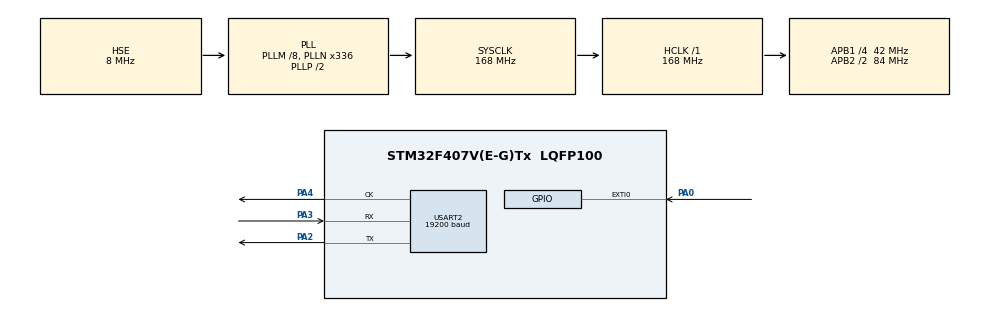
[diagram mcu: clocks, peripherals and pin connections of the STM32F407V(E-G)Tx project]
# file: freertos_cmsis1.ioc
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FREERTOS.Queues01=linCanQueue,16,uint16_t,0,Dynamic,NULL,NULL
FREERTOS.Tasks01=linReceiverTask,0,128,StartLinReceiverTask,Default,NULL,Dynamic,NULL,NULL;canSenderTask,-3,128,StartCanSenderTask,Default,NULL,Dynamic,NULL,NULL;myTask03,-3,128,StartTask03,Default,NULL,Dynamic,NULL,NULL
Mcu.Family=STM32F4
Mcu.Name=STM32F407V(E-G)Tx
Mcu.Package=LQFP100
NVIC.EXTI0_IRQn=true\:5\:0\:false\:false\:true\:true\:true\:true
NVIC.PriorityGroup=NVIC_PRIORITYGROUP_4
NVIC.TIM6_DAC_IRQn=true\:0\:0\:false\:false\:true\:false\:false\:true
NVIC.TimeBase=TIM6_DAC_IRQn
NVIC.TimeBaseIP=TIM6
PA0-WKUP.Signal=GPXTI0
PA13.Mode=Serial_Wire
PA13.Signal=SYS_JTMS-SWDIO
PA14.Mode=Serial_Wire
PA14.Signal=SYS_JTCK-SWCLK
PA2.Mode=Synchronous
PA2.Signal=USART2_TX
PA3.Mode=Synchronous
PA3.Signal=USART2_RX
PA4.Mode=Synchronous
PA4.Signal=USART2_CK
PH0-OSC_IN.Mode=HSE-External-Oscillator
PH0-OSC_IN.Signal=RCC_OSC_IN
PH1-OSC_OUT.Mode=HSE-External-Oscillator
PH1-OSC_OUT.Signal=RCC_OSC_OUT
ProjectManager.HeapSize=0x200
ProjectManager.StackSize=0x400
ProjectManager.TargetToolchain=STM32CubeIDE
RCC.48MHZClocksFreq_Value=48000000
RCC.AHBFreq_Value=168000000
RCC.APB1CLKDivider=RCC_HCLK_DIV4
RCC.APB1Freq_Value=42000000
RCC.APB1TimFreq_Value=84000000
RCC.APB2CLKDivider=RCC_HCLK_DIV2
RCC.APB2Freq_Value=84000000
RCC.APB2TimFreq_Value=168000000
RCC.CortexFreq_Value=168000000
RCC.HCLKFreq_Value=168000000
RCC.HSE_VALUE=8000000
RCC.HSI_VALUE=16000000
RCC.LSE_VALUE=32768
RCC.PLLM=8
RCC.PLLN=336
RCC.PLLQ=7
RCC.PLLSourceVirtual=RCC_PLLSOURCE_HSE
RCC.SYSCLKFreq_VALUE=168000000
RCC.SYSCLKSource=RCC_SYSCLKSOURCE_PLLCLK
RCC.VCOOutputFreq_Value=336000000
USART2.BaudRate=19200
USART2.VirtualMode=VM_SYNC
VP_FREERTOS_VS_CMSIS_V1.Mode=CMSIS_V1
VP_SYS_VS_tim6.Mode=TIM6
board=STM32F407G-DISC1

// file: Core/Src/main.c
/* USER CODE BEGIN Header */
/**
  ******************************************************************************
  * @file           : main.c
  * @brief          : Main program body
  ******************************************************************************
  * @attention
  *
  * Copyright (c) 2024 STMicroelectronics.
  * All rights reserved.
  *
  * This software is licensed under terms that can be found in the LICENSE file
  * in the root directory of this software component.
  * If no LICENSE file comes with this software, it is provided AS-IS.
  *
  ******************************************************************************
  */
/* USER CODE END Header */
#include "main.h"
#include "cmsis_os.h"

/* USER CODE BEGIN Includes */
#include <stdio.h>
#include "can.h"
#include "phares.h"
#include "commodos.h"
#include "UART_LIN.h"
#include "usart2.h"
#include "spi.h"
#include "lis3dsh.h"
/* USER CODE END Includes */

USART_HandleTypeDef husart2;

osThreadId linSenderTaskHandle;
osThreadId canReceiverTaskHandle;
osThreadId myTask04Handle;
osThreadId canTrackerTaskHandle;
osThreadId acceleroTaskHandle;
osMessageQId linCanQueueHandle;
osMutexId myMutex01Handle;
/* USER CODE BEGIN PV */

unsigned char DisplayData[];
LINMSG Tx_Msg;
LINMSG Rx_Msg;
int new_request;
int i = 0;
int actual_data;
int should_read_id = 0;
int should_read_data = 0;
int should_checksum = 0;
int should_synch = 1;
int deactivate_interrupt = 0;
int id_readed = 0;
int sync_readed = 0;
//extern int action;
int reading_acc = 0;

// CAN integ
volatile CAN_frame CAN_RxMessage;
volatile CAN_frame CAN_RxMessages[10];
int i_can;
volatile int read_index;
volatile uint8_t emergency_data_read = 0;
volatile uint8_t can_read_data;
extern buffer_has_more_cycle;
extern int total_received;
volatile int lin_readed_index = 0;
extern int phare_state;
CAN_frame my_frame;
volatile CAN_frame received_frame;
/* USER CODE END PV */

void SystemClock_Config(void);
static void MX_GPIO_Init(void);
static void MX_USART2_Init(void);
void StartLinSenderTask(void const * argument);
void StartCanReceiverTask(void const * argument);
void StartTask04(void const * argument);
void StartCanTrackerTask(void const * argument);
void StartAcceleroTask(void const * argument);

/* USER CODE BEGIN 0 */
int _write(int file, char *ptr, int len){
	HAL_USART_Transmit(&husart2, (uint8_t *)ptr, len, 10);
	return len;
}
/* USER CODE END 0 */

int main(void)
{

  /* MCU Configuration--------------------------------------------------------*/

  /* Reset of all peripherals, Initializes the Flash interface and the Systick. */
  HAL_Init();

  /* Configure the system clock */
  SystemClock_Config();

  /* Initialize all configured peripherals */
  MX_GPIO_Init();
  MX_USART2_Init();
  /* USER CODE BEGIN 2 */
  UART_Init();
  CAN_config();
  CAN_config_filter(0, 0, 0x0, 0x10520312, 0x10035110);
  init_SPI();
  init_ACC();
  /* USER CODE END 2 */

  /* Create the mutex(es) */
  /* definition and creation of myMutex01 */
  osMutexDef(myMutex01);
  myMutex01Handle = osMutexCreate(osMutex(myMutex01));

  /* Create the queue(s) */
  /* definition and creation of linCanQueue */
  osMessageQDef(linCanQueue, 16, uint16_t);
  linCanQueueHandle = osMessageCreate(osMessageQ(linCanQueue), NULL);

  /* Create the thread(s) */
  /* definition and creation of linSenderTask */
  osThreadDef(linSenderTask, StartLinSenderTask, osPriorityNormal, 0, 128);
  linSenderTaskHandle = osThreadCreate(osThread(linSenderTask), NULL);

  /* definition and creation of canReceiverTask */
  osThreadDef(canReceiverTask, StartCanReceiverTask, osPriorityIdle, 0, 128);
  canReceiverTaskHandle = osThreadCreate(osThread(canReceiverTask), NULL);

  /* definition and creation of myTask04 */
  osThreadDef(myTask04, StartTask04, osPriorityIdle, 0, 128);
  myTask04Handle = osThreadCreate(osThread(myTask04), NULL);

  /* definition and creation of canTrackerTask */
  osThreadDef(canTrackerTask, StartCanTrackerTask, osPriorityIdle, 0, 128);
  canTrackerTaskHandle = osThreadCreate(osThread(canTrackerTask), NULL);

  /* definition and creation of acceleroTask */
  osThreadDef(acceleroTask, StartAcceleroTask, osPriorityIdle, 0, 128);
  acceleroTaskHandle = osThreadCreate(osThread(acceleroTask), NULL);

  /* Start scheduler */
  osKernelStart();

  /* We should never get here as control is now taken by the scheduler */

  /* Infinite loop */
  while (1)
  {

  }
}

void SystemClock_Config(void)
{
  RCC_OscInitTypeDef RCC_OscInitStruct = {0};
  RCC_ClkInitTypeDef RCC_ClkInitStruct = {0};

  /** Configure the main internal regulator output voltage
  */
  __HAL_RCC_PWR_CLK_ENABLE();
  __HAL_PWR_VOLTAGESCALING_CONFIG(PWR_REGULATOR_VOLTAGE_SCALE1);

  /** Initializes the RCC Oscillators according to the specified parameters
  * in the RCC_OscInitTypeDef structure.
  */
  RCC_OscInitStruct.OscillatorType = RCC_OSCILLATORTYPE_HSE;
  RCC_OscInitStruct.HSEState = RCC_HSE_BYPASS;
  RCC_OscInitStruct.PLL.PLLState = RCC_PLL_ON;
  RCC_OscInitStruct.PLL.PLLSource = RCC_PLLSOURCE_HSE;
  RCC_OscInitStruct.PLL.PLLM = 8;
  RCC_OscInitStruct.PLL.PLLN = 336;
  RCC_OscInitStruct.PLL.PLLP = RCC_PLLP_DIV2;
  RCC_OscInitStruct.PLL.PLLQ = 7;
  if (HAL_RCC_OscConfig(&RCC_OscInitStruct) != HAL_OK)
  {
    Error_Handler();
  }

  /** Initializes the CPU, AHB and APB buses clocks
  */
  RCC_ClkInitStruct.ClockType = RCC_CLOCKTYPE_HCLK|RCC_CLOCKTYPE_SYSCLK
                              |RCC_CLOCKTYPE_PCLK1|RCC_CLOCKTYPE_PCLK2;
  RCC_ClkInitStruct.SYSCLKSource = RCC_SYSCLKSOURCE_PLLCLK;
  RCC_ClkInitStruct.AHBCLKDivider = RCC_SYSCLK_DIV1;
  RCC_ClkInitStruct.APB1CLKDivider = RCC_HCLK_DIV4;
  RCC_ClkInitStruct.APB2CLKDivider = RCC_HCLK_DIV2;

  if (HAL_RCC_ClockConfig(&RCC_ClkInitStruct, FLASH_LATENCY_5) != HAL_OK)
  {
    Error_Handler();
  }
}

static void MX_USART2_Init(void)
{

  husart2.Instance = USART2;
  husart2.Init.BaudRate = 19200;
  husart2.Init.WordLength = USART_WORDLENGTH_8B;
  husart2.Init.StopBits = USART_STOPBITS_1;
  husart2.Init.Parity = USART_PARITY_NONE;
  husart2.Init.Mode = USART_MODE_TX_RX;
  husart2.Init.CLKPolarity = USART_POLARITY_LOW;
  husart2.Init.CLKPhase = USART_PHASE_1EDGE;
  husart2.Init.CLKLastBit = USART_LASTBIT_DISABLE;
  if (HAL_USART_Init(&husart2) != HAL_OK)
  {
    Error_Handler();
  }

}

static void MX_GPIO_Init(void)
{
  GPIO_InitTypeDef GPIO_InitStruct = {0};

  /* GPIO Ports Clock Enable */
  __HAL_RCC_GPIOH_CLK_ENABLE();
  __HAL_RCC_GPIOA_CLK_ENABLE();
  __HAL_RCC_GPIOE_CLK_ENABLE();

  /*Configure GPIO pin : PE0 */
  GPIO_InitStruct.Pin = GPIO_PIN_0;
  GPIO_InitStruct.Mode = GPIO_MODE_IT_RISING;
  GPIO_InitStruct.Pull = GPIO_NOPULL;
  HAL_GPIO_Init(GPIOE, &GPIO_InitStruct);

  /* EXTI interrupt init*/
  HAL_NVIC_SetPriority(EXTI0_IRQn, 5, 0);
  HAL_NVIC_EnableIRQ(EXTI0_IRQn);

}

void StartLinSenderTask(void const * argument)
{
  /* USER CODE BEGIN 5 */
	int8_t lin_received_cnt = 0;
	uint8_t can_send_lin = 0;
  /* Infinite loop */
  for(;;)
  {
	  osSignalWait(1, osWaitForever);
	  lin_received_cnt++;
	  can_send_lin = 1;
	  int data = (unsigned int) CAN_RxMessage.data[0];

	  Tx_Msg.ID = LIN_SLAVE_WRITE_RTC_PID;
	  Tx_Msg.length = LIN_SLAVE_WRITE_RTC_LENGTH;

	  switch (CAN_RxMessage.STDID) {

		case COMMODO_CLIGNOTANT_RETURN_BASE:
				switch (data) {
					case COMMODO_CLIGNOTANT_REPOS_RETOURN_VALUE:
						Tx_Msg.ID = LIN_CLIGNO_STOP;
						printf("CLIGNO STOP \n\r");
						break;

					case COMMODO_CLIGNOTANT_DROIT_RETOURN_VALUE:
						Tx_Msg.ID = LIN_CLIGNO_DROIT;
						printf("CLIGNO DROIT \n\r");
						break;

					case COMMODO_CLIGNOTANT_GAUCHE_RETOURN_VALUE:
						Tx_Msg.ID = LIN_CLIGNO_GAUCHE;
						printf("CLIGNO GAUCHE \n\r");
						break;
					default:
						can_send_lin = 0;
						break;
				}
			break;

		case COMMODO_PHARE_RETURN_BASE:
				switch (data) {
					case COMMODO_PHARE_ALLUMER_RETOURN_VALUE:
						Tx_Msg.ID = LIN_PHARE_AVANT;
						printf("PHARES AVANT \n\r");
						break;

					case COMMODO_PHARE_VEILLEUSE_RETOURN_VALUE:
						Tx_Msg.ID = LIN_PHARE_ARRIERE;
						printf("PHARES ARRIERES \n\r");
						break;

					case COMMODO_PHARE_AUTO_RETOURN_VALUE:
						Tx_Msg.ID = LIN_PHARE_STOP;
						printf("PHARES STOP \n\r");
						break;
					default:
						can_send_lin = 0;
						break;
				}
			break;
		default:
			can_send_lin = 0;
			break;
	}

//	  Rx_Msg.ID = LIN_SLAVE_READ_RTC_PID;
//	  Rx_Msg.length = LIN_SLAVE_READ_RTC_LENGTH;
	  if(can_send_lin){

		  SendRequest(&Tx_Msg);
		  HAL_Delay(500);
		  printf("\n\r=================================\n\r");
	  }

	  osDelay(1000);
  }
  /* USER CODE END 5 */
}

void StartCanReceiverTask(void const * argument)
{
  /* USER CODE BEGIN StartCanReceiverTask */
	int8_t can_received_cnt = 0;

	osEvent canReadedTracker;
	int8_t executed_once = 0;

	CAN_frame auto_frame;
	  auto_frame.STDID = 0x10530310;
	  auto_frame.DLC = 1;
	  auto_frame.RTR = 0;
  /* Infinite loop */
  for(;;)
  {

	  	  // REAL CODE
	  canReadedTracker = osMessageGet(linCanQueueHandle, 1000);
	  if(canReadedTracker.value.v == 0x1){
		can_received_cnt++;
		osSignalSet(linSenderTaskHandle, 1);
		osDelay(1000);
	  }
  }
//    osSignalWait(1, osWaitForever);
  /* USER CODE END StartCanReceiverTask */
}

void StartTask04(void const * argument)
{
  /* USER CODE BEGIN StartTask04 */
	int cnt = 0;
  /* Infinite loop */
  for(;;)
  {
    osSignalWait(1, osWaitForever);
    cnt++;
//    printf("Donnée Can recue %d \n \r", cnt);
//    HAL_Delay(500);

	osDelay(1000);
  }
  /* USER CODE END StartTask04 */
}

void StartCanTrackerTask(void const * argument)
{
  /* USER CODE BEGIN StartCanTrackerTask */
	  int8_t cnt = 0;
  /* Infinite loop */
  for(;;)
  {
	printf("Waiting for CAN \n \r");
	osSignalWait(1, osWaitForever);
	cnt++;
	CAN_readFrame();
	printf("Readed CAN n° %d \n \r", cnt);
	HAL_Delay(100);

//	CAN_readFrame();
//	HAL_Delay(100);

//	printf("CAN Readed \n \r");
//	HAL_Delay(100);
	//	HAL_Delay(100);
	if(CAN_RxMessage.STDID == COMMODO_PHARE_RETURN_ID){
		if(CAN_RxMessage.data[0] == COMMODO_PHARE_RETURN_VALUE){
			uint8_t toto = 0;
		}else{
			uint8_t toto = 1;
		}
	}

	osDelay(1000);
//	osSignalSet(canTrackerTaskHandle, 1);

  }
  /* USER CODE END StartCanTrackerTask */
}

void StartAcceleroTask(void const * argument)
{
  /* USER CODE BEGIN StartAcceleroTask */
	double x = 0;
	double y = 0;
	double z = 0;
	uint8_t state_updated = 0;
  /* Infinite loop */
  for(;;)
  {
	  osSignalWait(1, osWaitForever);

	  x = get_ACC_X();
	  y = get_ACC_Y();
	  z = get_ACC_Z();
	  Tx_Msg.ID = LIN_SLAVE_WRITE_RTC_PID;
	  Tx_Msg.length = 0;

	  if(x < SEUIL_ARRIERE){
		  serial_puts("ARRIERE");
		  newLine();
		  Tx_Msg.ID = LIN_PHARE_ARRIERE;
		  state_updated = 1;
	  }
	  else if(x > SEUIL_AVANT){
		  serial_puts("AVANT");
		  newLine();
		  Tx_Msg.ID = LIN_PHARE_AVANT;
		  state_updated = 1;
	  }
	  else if(y < SEUIL_DROIT){
		  serial_puts("DROIT");
		  newLine();
		  Tx_Msg.ID = LIN_CLIGNO_DROIT;
		  state_updated = 1;
	  }
	  else if(y > SEUIL_GAUCHE){
		  serial_puts("GAUCHE");
		  newLine();
		  Tx_Msg.ID = LIN_CLIGNO_GAUCHE;
		  state_updated = 1;
	  }

//	  if(!state_updated){
	  else{
		  Tx_Msg.ID = LIN_RESET;
		  state_updated = 0;
		  serial_puts("RESET");
		  newLine();
	  }

	  SendRequest(&Tx_Msg);
	  HAL_Delay(100);
  }
  /* USER CODE END StartAcceleroTask */
}

void HAL_TIM_PeriodElapsedCallback(TIM_HandleTypeDef *htim)
{
  if (htim->Instance == TIM6) {
    HAL_IncTick();
  }
}

void Error_Handler(void)
{
  __disable_irq();
  while (1)
  {
  }
}
